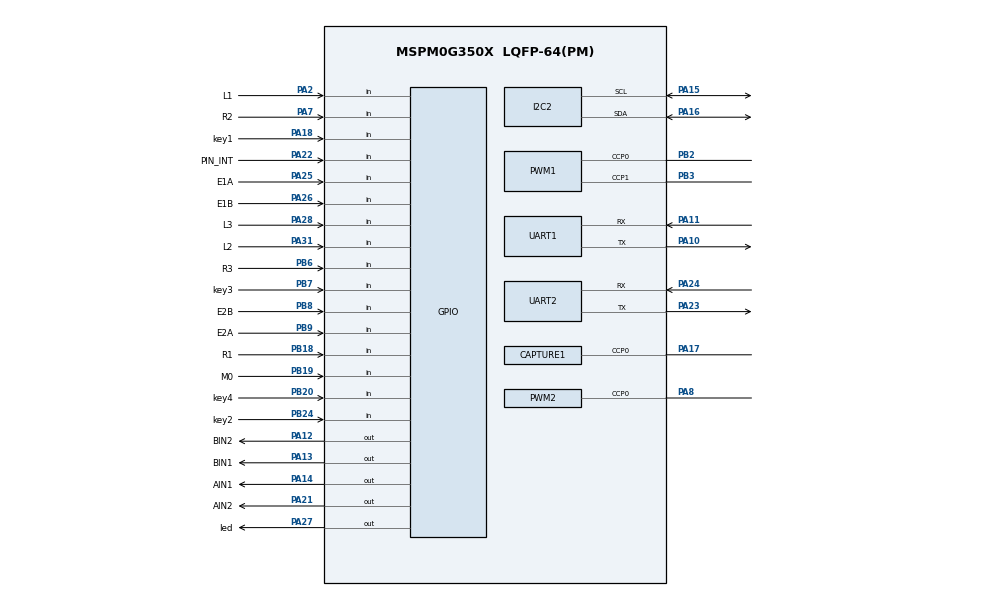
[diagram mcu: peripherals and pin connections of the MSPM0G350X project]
/**
 * @cliArgs --device "MSPM0G350X" --part "Default" --package "LQFP-64(PM)" --product "mspm0_sdk@2.05.01.00"
 * @versions {"tool":"1.24.2+4234"}
 */

/**
 * Import the modules used in this configuration.
 */
const CAPTURE  = scripting.addModule("/ti/driverlib/CAPTURE", {}, false);
const CAPTURE1 = CAPTURE.addInstance();
const GPIO     = scripting.addModule("/ti/driverlib/GPIO", {}, false);
const GPIO1    = GPIO.addInstance();
const GPIO2    = GPIO.addInstance();
const GPIO3    = GPIO.addInstance();
const GPIO4    = GPIO.addInstance();
const GPIO5    = GPIO.addInstance();
const GPIO6    = GPIO.addInstance();
const GPIO7    = GPIO.addInstance();
const GPIO8    = GPIO.addInstance();
const I2C      = scripting.addModule("/ti/driverlib/I2C", {}, false);
const I2C1     = I2C.addInstance();
const I2C2     = I2C.addInstance();
const PWM      = scripting.addModule("/ti/driverlib/PWM", {}, false);
const PWM1     = PWM.addInstance();
const PWM2     = PWM.addInstance();
const SYSCTL   = scripting.addModule("/ti/driverlib/SYSCTL");
const SYSTICK  = scripting.addModule("/ti/driverlib/SYSTICK");
const TIMER    = scripting.addModule("/ti/driverlib/TIMER", {}, false);
const TIMER1   = TIMER.addInstance();
const TIMER2   = TIMER.addInstance();
const UART     = scripting.addModule("/ti/driverlib/UART", {}, false);
const UART1    = UART.addInstance();
const UART2    = UART.addInstance();

/**
 * Write custom configuration values to the imported modules.
 */
const divider7       = system.clockTree["PLL_PDIV"];
divider7.divideValue = 2;

const divider9       = system.clockTree["UDIV"];
divider9.divideValue = 2;

const gate7  = system.clockTree["MFCLKGATE"];
gate7.enable = true;

const multiplier2         = system.clockTree["PLL_QDIV"];
multiplier2.multiplyValue = 5;

const mux8       = system.clockTree["HSCLKMUX"];
mux8.inputSelect = "HSCLKMUX_SYSPLL2X";

CAPTURE1.$name                              = "CAPTURE_ULTRASONIC";
CAPTURE1.timerClkPrescale                   = 80;
CAPTURE1.timerPeriod                        = "50 ms";
CAPTURE1.captMode                           = "PULSE_WIDTH_UP";
CAPTURE1.peripheral.$assign                 = "TIMG7";
CAPTURE1.peripheral.ccp0Pin.$assign         = "PA17";
CAPTURE1.ccp0PinConfig.hideOutputInversion  = scripting.forceWrite(false);
CAPTURE1.ccp0PinConfig.onlyInternalResistor = scripting.forceWrite(false);
CAPTURE1.ccp0PinConfig.passedPeripheralType = scripting.forceWrite("Digital");
CAPTURE1.ccp0PinConfig.$name                = "ti_driverlib_gpio_GPIOPinGeneric11";

const Board = scripting.addModule("/ti/driverlib/Board", {}, false);

GPIO1.$name                              = "KEY";
GPIO1.associatedPins.create(4);
GPIO1.associatedPins[0].direction        = "INPUT";
GPIO1.associatedPins[0].$name            = "key1";
GPIO1.associatedPins[0].pin.$assign      = "PA18";
GPIO1.associatedPins[1].$name            = "key2";
GPIO1.associatedPins[1].direction        = "INPUT";
GPIO1.associatedPins[1].internalResistor = "PULL_UP";
GPIO1.associatedPins[1].pin.$assign      = "PB24";
GPIO1.associatedPins[2].$name            = "key3";
GPIO1.associatedPins[2].direction        = "INPUT";
GPIO1.associatedPins[2].internalResistor = "PULL_UP";
GPIO1.associatedPins[2].pin.$assign      = "PB7";
GPIO1.associatedPins[3].$name            = "key4";
GPIO1.associatedPins[3].direction        = "INPUT";
GPIO1.associatedPins[3].internalResistor = "PULL_UP";
GPIO1.associatedPins[3].pin.$assign      = "PB20";

GPIO2.$name                         = "LED";
GPIO2.associatedPins[0].$name       = "led";
GPIO2.associatedPins[0].pin.$assign = "PA27";

GPIO3.port                          = "PORTA";
GPIO3.$name                         = "BIN";
GPIO3.associatedPins.create(2);
GPIO3.associatedPins[0].$name       = "BIN1";
GPIO3.associatedPins[0].pin.$assign = "PA13";
GPIO3.associatedPins[1].$name       = "BIN2";
GPIO3.associatedPins[1].pin.$assign = "PA12";

GPIO4.port                          = "PORTA";
GPIO4.$name                         = "AIN";
GPIO4.associatedPins.create(2);
GPIO4.associatedPins[0].$name       = "AIN1";
GPIO4.associatedPins[0].pin.$assign = "PA14";
GPIO4.associatedPins[1].$name       = "AIN2";
GPIO4.associatedPins[1].pin.$assign = "PA21";

GPIO5.$name                               = "ENCODERA";
GPIO5.associatedPins.create(2);
GPIO5.associatedPins[0].$name             = "E1A";
GPIO5.associatedPins[0].direction         = "INPUT";
GPIO5.associatedPins[0].interruptEn       = true;
GPIO5.associatedPins[0].internalResistor  = "PULL_UP";
GPIO5.associatedPins[0].interruptPriority = "0";
GPIO5.associatedPins[0].polarity          = "RISE_FALL";
GPIO5.associatedPins[0].pin.$assign       = "PA25";
GPIO5.associatedPins[1].$name             = "E1B";
GPIO5.associatedPins[1].direction         = "INPUT";
GPIO5.associatedPins[1].interruptEn       = true;
GPIO5.associatedPins[1].internalResistor  = "PULL_UP";
GPIO5.associatedPins[1].interruptPriority = "0";
GPIO5.associatedPins[1].polarity          = "RISE_FALL";
GPIO5.associatedPins[1].pin.$assign       = "PA26";

GPIO6.$name                               = "ENCODERB";
GPIO6.associatedPins.create(2);
GPIO6.associatedPins[0].$name             = "E2A";
GPIO6.associatedPins[0].direction         = "INPUT";
GPIO6.associatedPins[0].interruptEn       = true;
GPIO6.associatedPins[0].internalResistor  = "PULL_DOWN";
GPIO6.associatedPins[0].interruptPriority = "0";
GPIO6.associatedPins[0].polarity          = "RISE_FALL";
GPIO6.associatedPins[0].pin.$assign       = "PB9";
GPIO6.associatedPins[1].$name             = "E2B";
GPIO6.associatedPins[1].direction         = "INPUT";
GPIO6.associatedPins[1].interruptEn       = true;
GPIO6.associatedPins[1].internalResistor  = "PULL_DOWN";
GPIO6.associatedPins[1].interruptPriority = "0";
GPIO6.associatedPins[1].polarity          = "RISE_FALL";
GPIO6.associatedPins[1].pin.$assign       = "PB8";

GPIO7.$name                              = "HX_X17";
GPIO7.associatedPins.create(7);
GPIO7.associatedPins[0].$name            = "L3";
GPIO7.associatedPins[0].direction        = "INPUT";
GPIO7.associatedPins[0].internalResistor = "PULL_UP";
GPIO7.associatedPins[0].pin.$assign      = "PA28";
GPIO7.associatedPins[1].$name            = "L2";
GPIO7.associatedPins[1].direction        = "INPUT";
GPIO7.associatedPins[1].internalResistor = "PULL_UP";
GPIO7.associatedPins[1].pin.$assign      = "PA31";
GPIO7.associatedPins[2].$name            = "L1";
GPIO7.associatedPins[2].direction        = "INPUT";
GPIO7.associatedPins[2].internalResistor = "PULL_UP";
GPIO7.associatedPins[2].pin.$assign      = "PA2";
GPIO7.associatedPins[3].$name            = "M0";
GPIO7.associatedPins[3].direction        = "INPUT";
GPIO7.associatedPins[3].internalResistor = "PULL_UP";
GPIO7.associatedPins[3].pin.$assign      = "PB19";
GPIO7.associatedPins[4].$name            = "R1";
GPIO7.associatedPins[4].direction        = "INPUT";
GPIO7.associatedPins[4].internalResistor = "PULL_UP";
GPIO7.associatedPins[4].pin.$assign      = "PB18";
GPIO7.associatedPins[5].$name            = "R2";
GPIO7.associatedPins[5].direction        = "INPUT";
GPIO7.associatedPins[5].internalResistor = "PULL_UP";
GPIO7.associatedPins[5].pin.$assign      = "PA7";
GPIO7.associatedPins[6].$name            = "R3";
GPIO7.associatedPins[6].direction        = "INPUT";
GPIO7.associatedPins[6].internalResistor = "PULL_UP";
GPIO7.associatedPins[6].pin.$assign      = "PB6";

GPIO8.$name                               = "GPIO_MPU6050";
GPIO8.associatedPins[0].$name             = "PIN_INT";
GPIO8.associatedPins[0].direction         = "INPUT";
GPIO8.associatedPins[0].internalResistor  = "PULL_UP";
GPIO8.associatedPins[0].interruptEn       = true;
GPIO8.associatedPins[0].interruptPriority = "1";
GPIO8.associatedPins[0].polarity          = "FALL";
GPIO8.associatedPins[0].pin.$assign       = "PA22";

I2C1.$name                             = "OLED";
I2C1.basicEnableController             = true;
I2C1.basicControllerStandardBusSpeed   = "Fast";
I2C1.sdaPinConfig.hideOutputInversion  = scripting.forceWrite(false);
I2C1.sdaPinConfig.onlyInternalResistor = scripting.forceWrite(false);
I2C1.sdaPinConfig.passedPeripheralType = scripting.forceWrite("Digital");
I2C1.sdaPinConfig.$name                = "ti_driverlib_gpio_GPIOPinGeneric8";
I2C1.sclPinConfig.hideOutputInversion  = scripting.forceWrite(false);
I2C1.sclPinConfig.onlyInternalResistor = scripting.forceWrite(false);
I2C1.sclPinConfig.passedPeripheralType = scripting.forceWrite("Digital");
I2C1.sclPinConfig.$name                = "ti_driverlib_gpio_GPIOPinGeneric9";

I2C2.basicEnableController             = true;
I2C2.basicControllerStandardBusSpeed   = "Fast";
I2C2.$name                             = "I2C_MPU6050";
I2C2.peripheral.$assign                = "I2C1";
I2C2.peripheral.sdaPin.$assign         = "PA16";
I2C2.peripheral.sclPin.$assign         = "PA15";
I2C2.sdaPinConfig.hideOutputInversion  = scripting.forceWrite(false);
I2C2.sdaPinConfig.onlyInternalResistor = scripting.forceWrite(false);
I2C2.sdaPinConfig.passedPeripheralType = scripting.forceWrite("Digital");
I2C2.sdaPinConfig.$name                = "ti_driverlib_gpio_GPIOPinGeneric1";
I2C2.sclPinConfig.hideOutputInversion  = scripting.forceWrite(false);
I2C2.sclPinConfig.onlyInternalResistor = scripting.forceWrite(false);
I2C2.sclPinConfig.passedPeripheralType = scripting.forceWrite("Digital");
I2C2.sclPinConfig.$name                = "ti_driverlib_gpio_GPIOPinGeneric10";

PWM1.$name                      = "PWM_0";
PWM1.timerStartTimer            = true;
PWM1.pwmMode                    = "EDGE_ALIGN_UP";
PWM1.timerCount                 = 8000;
PWM1.peripheral.$assign         = "TIMG6";
PWM1.peripheral.ccp0Pin.$assign = "PB2";
PWM1.peripheral.ccp1Pin.$assign = "PB3";
PWM1.PWM_CHANNEL_0.$name        = "ti_driverlib_pwm_PWMTimerCC0";
PWM1.PWM_CHANNEL_1.$name        = "ti_driverlib_pwm_PWMTimerCC1";
PWM1.ccp0PinConfig.$name        = "ti_driverlib_gpio_GPIOPinGeneric4";
PWM1.ccp1PinConfig.$name        = "ti_driverlib_gpio_GPIOPinGeneric5";

PWM2.$name                              = "PWM_ULTRASONIC";
PWM2.timerCount                         = 64000;
PWM2.clockPrescale                      = 250;
PWM2.timerStartTimer                    = true;
PWM2.ccIndex                            = [0];
PWM2.PWM_CHANNEL_0.$name                = "ti_driverlib_pwm_PWMTimerCC2";
PWM2.PWM_CHANNEL_0.dutyCycle            = 50;
PWM2.ccp0PinConfig.direction            = scripting.forceWrite("OUTPUT");
PWM2.ccp0PinConfig.hideOutputInversion  = scripting.forceWrite(false);
PWM2.ccp0PinConfig.onlyInternalResistor = scripting.forceWrite(false);
PWM2.ccp0PinConfig.passedPeripheralType = scripting.forceWrite("Digital");
PWM2.ccp0PinConfig.$name                = "ti_driverlib_gpio_GPIOPinGeneric0";
PWM2.peripheral.$assign                 = "TIMA0";
PWM2.peripheral.ccp0Pin.$assign         = "PA8";

SYSCTL.forceDefaultClkConfig = true;
SYSCTL.clockTreeEn           = true;
scripting.suppress("For best practices when the CPUCLK is running at 32MHz and above, clear the flash status bit using DL_FlashCTL_executeClearStatus\\(\\) before executing any flash operation\\. Otherwise there may be false positives\\.", SYSCTL);

SYSTICK.periodEnable  = true;
SYSTICK.systickEnable = true;
SYSTICK.period        = 16777216;

TIMER1.$name              = "TIMER_0";
TIMER1.timerClkPrescale   = 32;
TIMER1.timerMode          = "PERIODIC";
TIMER1.interrupts         = ["ZERO"];
TIMER1.timerPeriod        = "10 ms";
TIMER1.interruptPriority  = "0";
TIMER1.peripheral.$assign = "TIMG0";

TIMER2.$name              = "TIMER_1";
TIMER2.timerMode          = "PERIODIC";
TIMER2.timerPeriod        = "100 ms";
TIMER2.interrupts         = ["ZERO"];
TIMER2.timerClkPrescale   = 64;
TIMER2.timerStartTimer    = true;
TIMER2.interruptPriority  = "1";
TIMER2.timerClkDiv        = 2;
TIMER2.peripheral.$assign = "TIMG8";

UART1.$name                    = "UART_0";
UART1.profile                  = "CONFIG_PROFILE_1";
UART1.peripheral.rxPin.$assign = "PA11";
UART1.peripheral.txPin.$assign = "PA10";
UART1.txPinConfig.$name        = "ti_driverlib_gpio_GPIOPinGeneric2";
UART1.rxPinConfig.$name        = "ti_driverlib_gpio_GPIOPinGeneric3";

UART2.$name                            = "UART_BT";
UART2.enabledDMARXTriggers             = "DL_UART_DMA_INTERRUPT_RX";
UART2.peripheral.rxPin.$assign         = "PA24";
UART2.peripheral.txPin.$assign         = "PA23";
UART2.txPinConfig.direction            = scripting.forceWrite("OUTPUT");
UART2.txPinConfig.hideOutputInversion  = scripting.forceWrite(false);
UART2.txPinConfig.onlyInternalResistor = scripting.forceWrite(false);
UART2.txPinConfig.passedPeripheralType = scripting.forceWrite("Digital");
UART2.txPinConfig.$name                = "ti_driverlib_gpio_GPIOPinGeneric6";
UART2.rxPinConfig.hideOutputInversion  = scripting.forceWrite(false);
UART2.rxPinConfig.onlyInternalResistor = scripting.forceWrite(false);
UART2.rxPinConfig.passedPeripheralType = scripting.forceWrite("Digital");
UART2.rxPinConfig.$name                = "ti_driverlib_gpio_GPIOPinGeneric7";
UART2.DMA_CHANNEL_RX.$name             = "DMA_CH0";
UART2.DMA_CHANNEL_RX.addressMode       = "f2b";
UART2.DMA_CHANNEL_RX.srcLength         = "BYTE";
UART2.DMA_CHANNEL_RX.dstLength         = "BYTE";

/**
 * Pinmux solution for unlocked pins/peripherals. This ensures that minor changes to the automatic solver in a future
 * version of the tool will not impact the pinmux you originally saw.  These lines can be completely deleted in order to
 * re-solve from scratch.
 */
Board.peripheral.$suggestSolution                = "DEBUGSS";
Board.peripheral.swclkPin.$suggestSolution       = "PA20";
Board.peripheral.swdioPin.$suggestSolution       = "PA19";
I2C1.peripheral.$suggestSolution                 = "I2C0";
I2C1.peripheral.sdaPin.$suggestSolution          = "PA0";
I2C1.peripheral.sclPin.$suggestSolution          = "PA1";
UART1.peripheral.$suggestSolution                = "UART0";
UART2.peripheral.$suggestSolution                = "UART2";
UART2.DMA_CHANNEL_RX.peripheral.$suggestSolution = "DMA_CH0";
